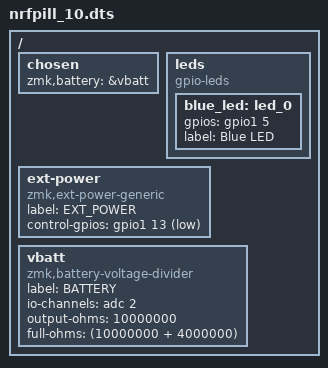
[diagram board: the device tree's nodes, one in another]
/*
 * Copyright (c) 2021 The ZMK Contributors
 *
 * SPDX-License-Identifier: MIT
 */

/dts-v1/;
#include "nrfpill.dtsi"

/ {
	chosen {
		zmk,battery = &vbatt;
	};

    leds {
		compatible = "gpio-leds";
		blue_led: led_0 {
			gpios = <&gpio1 5 GPIO_ACTIVE_HIGH>;
			label = "Blue LED";
		};
	};

/*ext-power sẽ cần bản PCB vá*/
	ext-power {
		compatible = "zmk,ext-power-generic";
		label = "EXT_POWER";
		control-gpios = <&gpio1 13 GPIO_ACTIVE_LOW>;
	};

	vbatt: vbatt {
		compatible = "zmk,battery-voltage-divider";
		label = "BATTERY";
		io-channels = <&adc 2>;
		output-ohms = <10000000>;
		full-ohms = <(10000000 + 4000000)>;
	};
};
